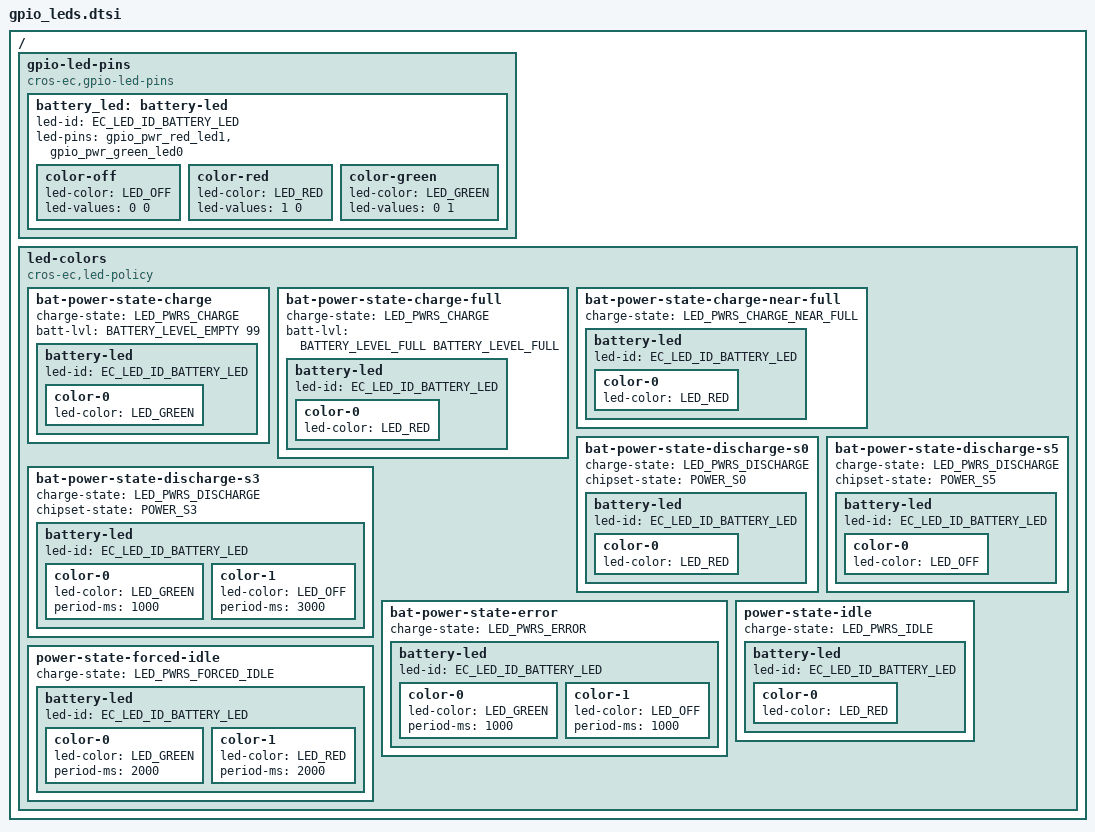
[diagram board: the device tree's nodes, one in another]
/* Copyright 2025 The ChromiumOS Authors
 * Use of this source code is governed by a BSD-style license that can be
 * found in the LICENSE file.
 */
#include <dt-bindings/battery.h>

/ {
	gpio-led-pins {
		compatible = "cros-ec,gpio-led-pins";

		battery_led: battery-led {
			led-id = "EC_LED_ID_BATTERY_LED";
			led-pins = <&gpio_pwr_red_led1 &gpio_pwr_green_led0>;

			color-off {
				led-color = "LED_OFF";
				led-values = <0 0>;
			};

			color-red {
				led-color = "LED_RED";
				led-values = <1 0>;
			};

			color-green {
				led-color = "LED_GREEN";
				led-values = <0 1>;
			};
		};
	};

	led-colors {
		compatible = "cros-ec,led-policy";

		/* PUJJONIRU LED bat charge */
		bat-power-state-charge {
			charge-state = "LED_PWRS_CHARGE";
			/* Battery display percent range (>= Empty, <= 99%) */
			batt-lvl = <BATTERY_LEVEL_EMPTY 99>;

			battery-led {
				led-id = "EC_LED_ID_BATTERY_LED";

				color-0 {
					led-color = "LED_GREEN";
				};
			};
		};

		/* PUJJONIRU LED bat charge, full batt-lvl */
		bat-power-state-charge-full {
			charge-state = "LED_PWRS_CHARGE";
			/* Battery display percent range (100%) */
			batt-lvl = <BATTERY_LEVEL_FULL BATTERY_LEVEL_FULL>;

			battery-led {
				led-id = "EC_LED_ID_BATTERY_LED";

				color-0 {
					led-color = "LED_RED";
				};
			};
		};

		/* PUJJONIRU LED bat charge near full */
		bat-power-state-charge-near-full {
			charge-state = "LED_PWRS_CHARGE_NEAR_FULL";

			battery-led {
				led-id = "EC_LED_ID_BATTERY_LED";

				color-0 {
					led-color = "LED_RED";
				};
			};
		};

		/* PUJJONIRU LED bat discharge */
		bat-power-state-discharge-s0 {
			charge-state = "LED_PWRS_DISCHARGE";
			chipset-state = "POWER_S0";

			battery-led {
				led-id = "EC_LED_ID_BATTERY_LED";

				color-0 {
					led-color = "LED_RED";
				};
			};
		};

		bat-power-state-discharge-s3 {
			charge-state = "LED_PWRS_DISCHARGE";
			chipset-state = "POWER_S3";

			battery-led {
				led-id = "EC_LED_ID_BATTERY_LED";

				color-0 {
					led-color = "LED_GREEN";
					period-ms = <1000>;
				};
				color-1 {
					led-color = "LED_OFF";
					period-ms = <3000>;
				};
			};
		};

		bat-power-state-discharge-s5 {
			charge-state = "LED_PWRS_DISCHARGE";
			chipset-state = "POWER_S5";

			battery-led {
				led-id = "EC_LED_ID_BATTERY_LED";

				color-0 {
					led-color = "LED_OFF";
				};
			};
		};

		/* PUJJONIRU LED bat error */
		bat-power-state-error {
			charge-state = "LED_PWRS_ERROR";

			battery-led {
				led-id = "EC_LED_ID_BATTERY_LED";

				color-0 {
					led-color = "LED_GREEN";
					period-ms = <1000>;
				};
				color-1 {
					led-color = "LED_OFF";
					period-ms = <1000>;
				};
			};
		};

		/* PUJJONIRU LED power idle */
		power-state-idle {
			charge-state = "LED_PWRS_IDLE";

			battery-led {
				led-id = "EC_LED_ID_BATTERY_LED";

				color-0 {
					led-color = "LED_RED";
				};
			};
		};

		/* PUJJONIRU LED power forced idle */
		power-state-forced-idle {
			charge-state = "LED_PWRS_FORCED_IDLE";

			battery-led {
				led-id = "EC_LED_ID_BATTERY_LED";

				color-0 {
					led-color = "LED_GREEN";
					period-ms = <2000>;
				};
				color-1 {
					led-color = "LED_RED";
					period-ms = <2000>;
				};
			};
		};
	};
};
